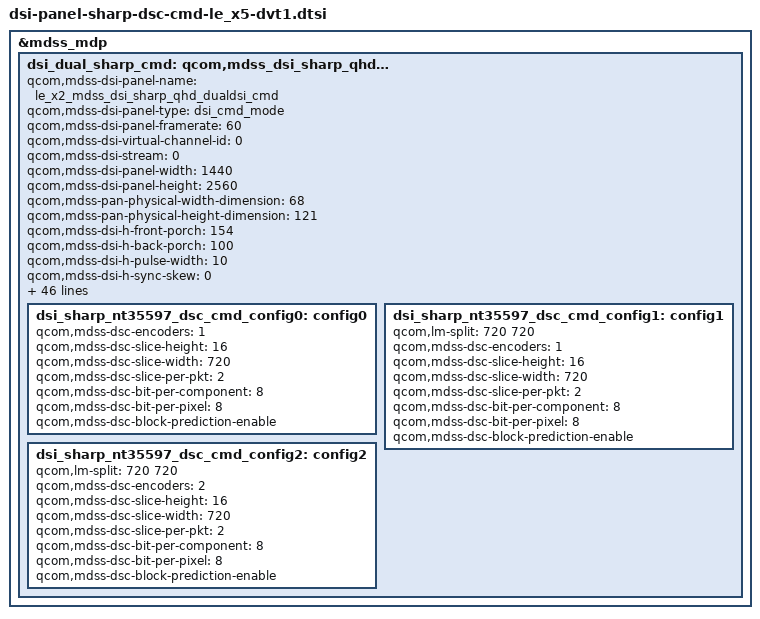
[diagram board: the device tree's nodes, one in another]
/* Copyright (c) 2013-2014, The Linux Foundation. All rights reserved.
 *
 * This program is free software; you can redistribute it and/or modify
 * it under the terms of the GNU General Public License version 2 and
 * only version 2 as published by the Free Software Foundation.
 *
 * This program is distributed in the hope that it will be useful,
 * but WITHOUT ANY WARRANTY; without even the implied warranty of
 * MERCHANTABILITY or FITNESS FOR A PARTICULAR PURPOSE.  See the
 * GNU General Public License for more details.
 */

&mdss_mdp {
	dsi_dual_sharp_cmd: qcom,mdss_dsi_sharp_qhd_dualdsi_cmd_le_x2 {
		qcom,mdss-dsi-panel-name = "le_x2_mdss_dsi_sharp_qhd_dualdsi_cmd";
		qcom,mdss-dsi-panel-type = "dsi_cmd_mode";
		qcom,mdss-dsi-panel-framerate = <60>;
		qcom,mdss-dsi-virtual-channel-id = <0>;
		qcom,mdss-dsi-stream = <0>;
		qcom,mdss-dsi-panel-width = <1440>;
		qcom,mdss-dsi-panel-height = <2560>;
		qcom,mdss-pan-physical-width-dimension = <68>;
		qcom,mdss-pan-physical-height-dimension = <121>;
		qcom,mdss-dsi-h-front-porch = <154>;
		qcom,mdss-dsi-h-back-porch = <100>;
		qcom,mdss-dsi-h-pulse-width = <10>;
		qcom,mdss-dsi-h-sync-skew = <0>;
		qcom,mdss-dsi-v-back-porch = <7>;
		qcom,mdss-dsi-v-front-porch = <8>;
		qcom,mdss-dsi-v-pulse-width = <1>;
		qcom,mdss-dsi-h-left-border = <0>;
		qcom,mdss-dsi-h-right-border = <0>;
		qcom,mdss-dsi-v-top-border = <0>;
		qcom,mdss-dsi-v-bottom-border = <0>;
		qcom,mdss-dsi-bpp = <24>;
		qcom,mdss-dsi-color-order = "rgb_swap_rgb";
		qcom,mdss-dsi-underflow-color = <0xff>;
		qcom,mdss-dsi-border-color = <0>;
		qcom,mdss-dsi-h-sync-pulse = <0>;
		qcom,mdss-dsi-traffic-mode = "non_burst_sync_event";
		qcom,mdss-dsi-bllp-eof-power-mode;
		qcom,mdss-dsi-bllp-power-mode;
		qcom,mdss-dsi-lane-0-state;
		qcom,mdss-dsi-lane-1-state;
		qcom,mdss-dsi-lane-2-state;
		qcom,mdss-dsi-lane-3-state;
		qcom,mdss-dsi-panel-timings = [cd 32 22 00 60 64 26 34 29 03
									04 00];
		qcom,mdss-dsi-reset-sequence = <1 10>, <0 10>, <1 10>;
		qcom,mdss-dsi-t-clk-post = <0x0d>;
		qcom,mdss-dsi-t-clk-pre = <0x30>;
		qcom,mdss-dsi-bl-max-level = <2047>;
		qcom,mdss-brightness-max-level = <2047>;
		qcom,mdss-dsi-dma-trigger = "trigger_sw";
		qcom,mdss-dsi-mdp-trigger = "none";
		qcom,mdss-dsi-te-pin-select = <1>;
		qcom,mdss-dsi-wr-mem-start = <0x2c>;
		qcom,mdss-dsi-wr-mem-continue = <0x3c>;
		qcom,mdss-dsi-te-dcs-command = <1>;
		qcom,mdss-dsi-te-check-enable;
		qcom,mdss-dsi-te-using-te-pin;
		qcom,ulps-enabled;
		qcom,mdss-dsi-on-command = [
					15 01 00 00 00 00 02 FF 28
					15 01 00 00 00 00 02 FB 01
					15 01 00 00 00 00 02 7A 02

					15 01 00 00 00 00 02 FF 10
					15 01 00 00 00 00 02 FB 01

					39 01 00 00 00 00 11 c1 09 20 00 20 02 00 02 68 03 87 00 0a 03 19 02 63
					15 01 00 00 00 00 03 c2 10 f0
					15 01 00 00 00 00 02 c0 03

					15 01 00 00 00 00 02 BA 03
					15 01 00 00 00 00 02 E5 01
					15 01 00 00 00 00 02 35 00
					15 01 00 00 00 00 02 BB 10
					15 01 00 00 00 00 02 B0 03
					39 01 00 00 00 00 06 3B 03 08 08 64 9A

					05 01 00 00 20 00 01 11               //SET DISLAY ON
					05 01 00 00 78 00 01 29
		];
					/* write control brightness */
		qcom,mdss-dsi-on-command-state = "dsi_lp_mode";
		qcom,mdss-dsi-off-command = [05 01 00 00 32 00 02 28 00
					05 01 00 00 78 00 02 10 00];
		qcom,mdss-dsi-off-command-state = "dsi_hs_mode";
		qcom,mdss-tear-check-sync-cfg-height = <2580>;


#if 1
		qcom,compression-mode = "dsc";
		qcom,config-select = <&dsi_sharp_nt35597_dsc_cmd_config2>;

		dsi_sharp_nt35597_dsc_cmd_config0: config0 {
			qcom,mdss-dsc-encoders = <1>;
			qcom,mdss-dsc-slice-height = <16>;
			qcom,mdss-dsc-slice-width = <720>;
			qcom,mdss-dsc-slice-per-pkt = <2>;

			qcom,mdss-dsc-bit-per-component = <8>;
			qcom,mdss-dsc-bit-per-pixel = <8>;
			qcom,mdss-dsc-block-prediction-enable;
		};

		dsi_sharp_nt35597_dsc_cmd_config1: config1 {
			qcom,lm-split = <720 720>;
			qcom,mdss-dsc-encoders = <1>; /* 3D Mux */
			qcom,mdss-dsc-slice-height = <16>;
			qcom,mdss-dsc-slice-width = <720>;
			qcom,mdss-dsc-slice-per-pkt = <2>;

			qcom,mdss-dsc-bit-per-component = <8>;
			qcom,mdss-dsc-bit-per-pixel = <8>;
			qcom,mdss-dsc-block-prediction-enable;
		};

		dsi_sharp_nt35597_dsc_cmd_config2: config2 {
			qcom,lm-split = <720 720>;
			qcom,mdss-dsc-encoders = <2>; /* DSC Merge */
			qcom,mdss-dsc-slice-height = <16>;
			qcom,mdss-dsc-slice-width = <720>;
			qcom,mdss-dsc-slice-per-pkt = <2>;

			qcom,mdss-dsc-bit-per-component = <8>;
			qcom,mdss-dsc-bit-per-pixel = <8>;
			qcom,mdss-dsc-block-prediction-enable;
		};
#endif
	};
};
